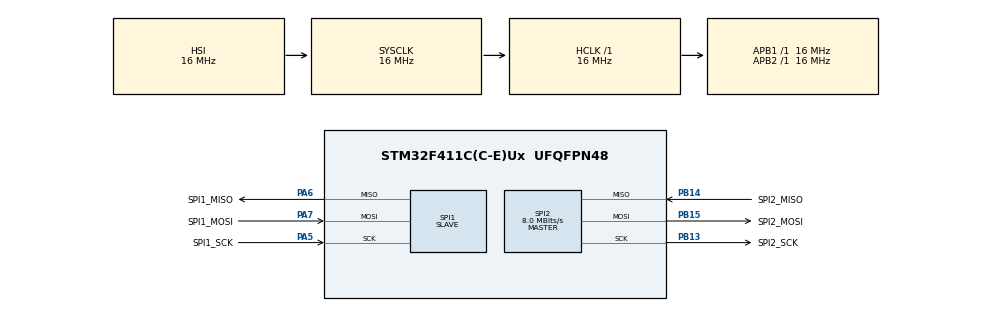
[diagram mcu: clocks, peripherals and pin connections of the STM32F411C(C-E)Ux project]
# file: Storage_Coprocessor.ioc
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Dma.Request0=SPI1_RX
Dma.Request1=SPI2_TX
Dma.Request2=SPI2_RX
Dma.Request3=SPI1_TX
Dma.SPI1_RX.0.Direction=DMA_PERIPH_TO_MEMORY
Dma.SPI1_RX.0.FIFOMode=DMA_FIFOMODE_ENABLE
Dma.SPI1_RX.0.FIFOThreshold=DMA_FIFO_THRESHOLD_FULL
Dma.SPI1_RX.0.Instance=DMA2_Stream0
Dma.SPI1_RX.0.MemBurst=DMA_MBURST_SINGLE
Dma.SPI1_RX.0.MemDataAlignment=DMA_MDATAALIGN_BYTE
Dma.SPI1_RX.0.MemInc=DMA_MINC_ENABLE
Dma.SPI1_RX.0.Mode=DMA_CIRCULAR
Dma.SPI1_RX.0.PeriphBurst=DMA_PBURST_SINGLE
Dma.SPI1_RX.0.PeriphDataAlignment=DMA_PDATAALIGN_BYTE
Dma.SPI1_RX.0.PeriphInc=DMA_PINC_DISABLE
Dma.SPI1_RX.0.Priority=DMA_PRIORITY_VERY_HIGH
Dma.SPI1_TX.3.Direction=DMA_MEMORY_TO_PERIPH
Dma.SPI1_TX.3.FIFOMode=DMA_FIFOMODE_ENABLE
Dma.SPI1_TX.3.FIFOThreshold=DMA_FIFO_THRESHOLD_FULL
Dma.SPI1_TX.3.Instance=DMA2_Stream2
Dma.SPI1_TX.3.MemBurst=DMA_MBURST_SINGLE
Dma.SPI1_TX.3.MemDataAlignment=DMA_MDATAALIGN_BYTE
Dma.SPI1_TX.3.MemInc=DMA_MINC_ENABLE
Dma.SPI1_TX.3.Mode=DMA_NORMAL
Dma.SPI1_TX.3.PeriphBurst=DMA_PBURST_SINGLE
Dma.SPI1_TX.3.PeriphDataAlignment=DMA_PDATAALIGN_BYTE
Dma.SPI1_TX.3.PeriphInc=DMA_PINC_DISABLE
Dma.SPI1_TX.3.Priority=DMA_PRIORITY_LOW
Dma.SPI2_RX.2.Direction=DMA_PERIPH_TO_MEMORY
Dma.SPI2_RX.2.FIFOMode=DMA_FIFOMODE_ENABLE
Dma.SPI2_RX.2.FIFOThreshold=DMA_FIFO_THRESHOLD_FULL
Dma.SPI2_RX.2.Instance=DMA1_Stream3
Dma.SPI2_RX.2.MemBurst=DMA_MBURST_SINGLE
Dma.SPI2_RX.2.MemDataAlignment=DMA_MDATAALIGN_BYTE
Dma.SPI2_RX.2.MemInc=DMA_MINC_ENABLE
Dma.SPI2_RX.2.Mode=DMA_NORMAL
Dma.SPI2_RX.2.PeriphBurst=DMA_PBURST_SINGLE
Dma.SPI2_RX.2.PeriphDataAlignment=DMA_PDATAALIGN_BYTE
Dma.SPI2_RX.2.PeriphInc=DMA_PINC_DISABLE
Dma.SPI2_RX.2.Priority=DMA_PRIORITY_MEDIUM
Dma.SPI2_TX.1.Direction=DMA_MEMORY_TO_PERIPH
Dma.SPI2_TX.1.FIFOMode=DMA_FIFOMODE_ENABLE
Dma.SPI2_TX.1.FIFOThreshold=DMA_FIFO_THRESHOLD_FULL
Dma.SPI2_TX.1.Instance=DMA1_Stream4
Dma.SPI2_TX.1.MemBurst=DMA_MBURST_SINGLE
Dma.SPI2_TX.1.MemDataAlignment=DMA_MDATAALIGN_BYTE
Dma.SPI2_TX.1.MemInc=DMA_MINC_ENABLE
Dma.SPI2_TX.1.Mode=DMA_NORMAL
Dma.SPI2_TX.1.PeriphBurst=DMA_PBURST_SINGLE
Dma.SPI2_TX.1.PeriphDataAlignment=DMA_PDATAALIGN_BYTE
Dma.SPI2_TX.1.PeriphInc=DMA_PINC_DISABLE
Dma.SPI2_TX.1.Priority=DMA_PRIORITY_HIGH
Mcu.Family=STM32F4
Mcu.Name=STM32F411C(C-E)Ux
Mcu.Package=UFQFPN48
NVIC.DMA1_Stream3_IRQn=true\:0\:0\:false\:false\:true\:false\:true\:true
NVIC.DMA1_Stream4_IRQn=true\:0\:0\:false\:false\:true\:false\:true\:true
NVIC.DMA2_Stream0_IRQn=true\:0\:0\:false\:false\:true\:false\:true\:true
NVIC.DMA2_Stream2_IRQn=true\:0\:0\:false\:false\:true\:false\:true\:true
NVIC.PriorityGroup=NVIC_PRIORITYGROUP_4
PA4.GPIO_Label=SPI1_NSS
PA4.Signal=SPI1_NSS
PA5.GPIO_Label=SPI1_SCK
PA5.Mode=Full_Duplex_Slave
PA5.Signal=SPI1_SCK
PA6.GPIO_Label=SPI1_MISO
PA6.Mode=Full_Duplex_Slave
PA6.Signal=SPI1_MISO
PA7.GPIO_Label=SPI1_MOSI
PA7.Mode=Full_Duplex_Slave
PA7.Signal=SPI1_MOSI
PB12.GPIO_Label=SPI2_NSS
PB12.Signal=SPI2_NSS
PB13.GPIO_Label=SPI2_SCK
PB13.Mode=Full_Duplex_Master
PB13.Signal=SPI2_SCK
PB14.GPIO_Label=SPI2_MISO
PB14.Mode=Full_Duplex_Master
PB14.Signal=SPI2_MISO
PB15.GPIO_Label=SPI2_MOSI
PB15.Mode=Full_Duplex_Master
PB15.Signal=SPI2_MOSI
ProjectManager.HeapSize=0x200
ProjectManager.StackSize=0x400
ProjectManager.TargetToolchain=STM32CubeIDE
RCC.AHBFreq_Value=16000000
RCC.APB1Freq_Value=16000000
RCC.APB2Freq_Value=16000000
RCC.CortexFreq_Value=16000000
RCC.HSE_VALUE=25000000
RCC.HSI_VALUE=16000000
RCC.LSE_VALUE=32768
RCC.SYSCLKFreq_VALUE=16000000
RCC.VCOOutputFreq_Value=192000000
SPI1.CRCCalculation=SPI_CRCCALCULATION_ENABLE
SPI1.DataSize=SPI_DATASIZE_8BIT
SPI1.Direction=SPI_DIRECTION_2LINES
SPI1.Mode=SPI_MODE_SLAVE
SPI1.VirtualType=VM_SLAVE
SPI2.CRCCalculation=SPI_CRCCALCULATION_ENABLE
SPI2.CalculateBaudRate=8.0 MBits/s
SPI2.Direction=SPI_DIRECTION_2LINES
SPI2.Mode=SPI_MODE_MASTER
SPI2.VirtualType=VM_MASTER
board=custom

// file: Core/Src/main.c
/* USER CODE BEGIN Header */
/**
  ******************************************************************************
  * @file           : main.c
  * @brief          : Main program body
  ******************************************************************************
  * @attention
  *
  * Copyright (c) 2026 STMicroelectronics.
  * All rights reserved.
  *
  * This software is licensed under terms that can be found in the LICENSE file
  * in the root directory of this software component.
  * If no LICENSE file comes with this software, it is provided AS-IS.
  *
  ******************************************************************************
  */
/* USER CODE END Header */
#include "main.h"

/* USER CODE BEGIN Includes */
#include "storage_main.h"
#include "benchmark.h"
/* USER CODE END Includes */

SPI_HandleTypeDef hspi1;
SPI_HandleTypeDef hspi2;
DMA_HandleTypeDef hdma_spi1_rx;
DMA_HandleTypeDef hdma_spi1_tx;
DMA_HandleTypeDef hdma_spi2_tx;
DMA_HandleTypeDef hdma_spi2_rx;

void SystemClock_Config(void);
static void MX_GPIO_Init(void);
static void MX_DMA_Init(void);
static void MX_SPI1_Init(void);
static void MX_SPI2_Init(void);

int main(void)
{

  /* MCU Configuration--------------------------------------------------------*/

  /* Reset of all peripherals, Initializes the Flash interface and the Systick. */
  HAL_Init();

  /* Configure the system clock */
  SystemClock_Config();

  /* Initialize all configured peripherals */
  MX_GPIO_Init();
  MX_DMA_Init();
  MX_SPI1_Init();
  MX_SPI2_Init();
  /* USER CODE BEGIN 2 */

  // Initialize the FTL and queues (optional, handled by config but safe to init)
  // Run the benchmark test
  Benchmark_Run();

  /* USER CODE END 2 */

  /* Infinite loop */
  while (1)
  {

  }
}

void SystemClock_Config(void)
{
  RCC_OscInitTypeDef RCC_OscInitStruct = {0};
  RCC_ClkInitTypeDef RCC_ClkInitStruct = {0};

  /** Configure the main internal regulator output voltage
  */
  __HAL_RCC_PWR_CLK_ENABLE();
  __HAL_PWR_VOLTAGESCALING_CONFIG(PWR_REGULATOR_VOLTAGE_SCALE1);

  /** Initializes the RCC Oscillators according to the specified parameters
  * in the RCC_OscInitTypeDef structure.
  */
  RCC_OscInitStruct.OscillatorType = RCC_OSCILLATORTYPE_HSI;
  RCC_OscInitStruct.HSIState = RCC_HSI_ON;
  RCC_OscInitStruct.HSICalibrationValue = RCC_HSICALIBRATION_DEFAULT;
  RCC_OscInitStruct.PLL.PLLState = RCC_PLL_NONE;
  if (HAL_RCC_OscConfig(&RCC_OscInitStruct) != HAL_OK)
  {
    Error_Handler();
  }

  /** Initializes the CPU, AHB and APB buses clocks
  */
  RCC_ClkInitStruct.ClockType = RCC_CLOCKTYPE_HCLK|RCC_CLOCKTYPE_SYSCLK
                              |RCC_CLOCKTYPE_PCLK1|RCC_CLOCKTYPE_PCLK2;
  RCC_ClkInitStruct.SYSCLKSource = RCC_SYSCLKSOURCE_HSI;
  RCC_ClkInitStruct.AHBCLKDivider = RCC_SYSCLK_DIV1;
  RCC_ClkInitStruct.APB1CLKDivider = RCC_HCLK_DIV1;
  RCC_ClkInitStruct.APB2CLKDivider = RCC_HCLK_DIV1;

  if (HAL_RCC_ClockConfig(&RCC_ClkInitStruct, FLASH_LATENCY_0) != HAL_OK)
  {
    Error_Handler();
  }
}

static void MX_SPI1_Init(void)
{

  /* SPI1 parameter configuration*/
  hspi1.Instance = SPI1;
  hspi1.Init.Mode = SPI_MODE_SLAVE;
  hspi1.Init.Direction = SPI_DIRECTION_2LINES;
  hspi1.Init.DataSize = SPI_DATASIZE_8BIT;
  hspi1.Init.CLKPolarity = SPI_POLARITY_LOW;
  hspi1.Init.CLKPhase = SPI_PHASE_1EDGE;
  hspi1.Init.NSS = SPI_NSS_SOFT;
  hspi1.Init.FirstBit = SPI_FIRSTBIT_MSB;
  hspi1.Init.TIMode = SPI_TIMODE_DISABLE;
  hspi1.Init.CRCCalculation = SPI_CRCCALCULATION_ENABLE;
  hspi1.Init.CRCPolynomial = 10;
  if (HAL_SPI_Init(&hspi1) != HAL_OK)
  {
    Error_Handler();
  }

}

static void MX_SPI2_Init(void)
{

  /* SPI2 parameter configuration*/
  hspi2.Instance = SPI2;
  hspi2.Init.Mode = SPI_MODE_MASTER;
  hspi2.Init.Direction = SPI_DIRECTION_2LINES;
  hspi2.Init.DataSize = SPI_DATASIZE_8BIT;
  hspi2.Init.CLKPolarity = SPI_POLARITY_LOW;
  hspi2.Init.CLKPhase = SPI_PHASE_1EDGE;
  hspi2.Init.NSS = SPI_NSS_SOFT;
  hspi2.Init.BaudRatePrescaler = SPI_BAUDRATEPRESCALER_2;
  hspi2.Init.FirstBit = SPI_FIRSTBIT_MSB;
  hspi2.Init.TIMode = SPI_TIMODE_DISABLE;
  hspi2.Init.CRCCalculation = SPI_CRCCALCULATION_ENABLE;
  hspi2.Init.CRCPolynomial = 10;
  if (HAL_SPI_Init(&hspi2) != HAL_OK)
  {
    Error_Handler();
  }

}

static void MX_DMA_Init(void)
{

  /* DMA controller clock enable */
  __HAL_RCC_DMA2_CLK_ENABLE();
  __HAL_RCC_DMA1_CLK_ENABLE();

  /* DMA interrupt init */
  /* DMA1_Stream3_IRQn interrupt configuration */
  HAL_NVIC_SetPriority(DMA1_Stream3_IRQn, 0, 0);
  HAL_NVIC_EnableIRQ(DMA1_Stream3_IRQn);
  /* DMA1_Stream4_IRQn interrupt configuration */
  HAL_NVIC_SetPriority(DMA1_Stream4_IRQn, 0, 0);
  HAL_NVIC_EnableIRQ(DMA1_Stream4_IRQn);
  /* DMA2_Stream0_IRQn interrupt configuration */
  HAL_NVIC_SetPriority(DMA2_Stream0_IRQn, 0, 0);
  HAL_NVIC_EnableIRQ(DMA2_Stream0_IRQn);
  /* DMA2_Stream2_IRQn interrupt configuration */
  HAL_NVIC_SetPriority(DMA2_Stream2_IRQn, 0, 0);
  HAL_NVIC_EnableIRQ(DMA2_Stream2_IRQn);

}

static void MX_GPIO_Init(void)
{

  /* GPIO Ports Clock Enable */
  __HAL_RCC_GPIOA_CLK_ENABLE();
  __HAL_RCC_GPIOB_CLK_ENABLE();

}

void Error_Handler(void)
{
  __disable_irq();
  while (1)
  {
  }
}
